# TLE9563 register map
Vendor: Infineon; File version: 0.2.0
Registers are 16-bit, read-write, reset 0x0 unless marked. A register's access mark holds for its fields unless they carry their own. Offsets are from the block's base; lines under a group give offsets from that group; [hi:lo] are bit positions; {n}, {i} and the like mark numbered series; 'fields as' and 'values as' point back to an identical list; <NAME> marks a mode.

## Memory map
0x00000000 TLE9563 size 0x4000 — TLE9563 Module

## TLE9563 — TLE9563 Module
Base 0x00000000
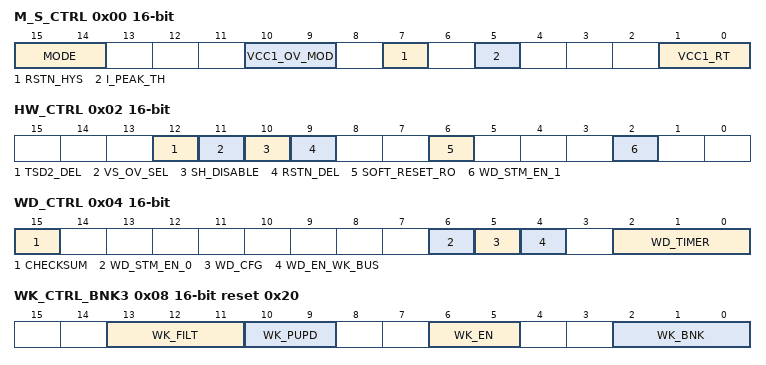
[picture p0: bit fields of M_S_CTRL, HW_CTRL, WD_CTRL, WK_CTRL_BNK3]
0x00 M_S_CTRL access per field (reset mask 0xE7) — Mode and Supply Control
  [15:14] MODE read-write-hardware — Device Mode Control
    0=NORMAL, Normal Mode; 1=SLEEP, Sleep Mode; 2=STOP, Stop Mode; 3=RESET, Device reset Soft reset is executed (configuration of RSTN triggering in bit SOFT_RESET_RO)
  [10:9] VCC1_OV_MOD read-write-hardware — Reaction in case of VCC1 Over Voltage
    0=NO, no reaction; 1=INTN, INTN event is generated; 2=RSTN, RSTN event is generated; 3=FAILSAFE, Fail-Safe Mode is entered
  [7] RSTN_HYS rw — VCC1 Undervoltage Reset Hysteresis Selection (see also Chapter 12.7.1 for more information)
    0=DEFAULT, default hysteresis applies as specified in the electrical characteristics table; 1=HIGHEST, the highest rising threshold (VRT1,R) is always used for the release of the undervoltage reset
  [5] I_PEAK_TH rw — VCC1 Active Peak Threshold Selection
    0=LOW, low VCC1 active peak threshold selected; 1=HIGH, high VCC1 active peak threshold selected
  [1:0] VCC1_RT rw — VCC1 Reset Threshold Control
    0=VRT1, Vrt1 selected (highest threshold); 1=VRT2, Vrt2 selected; 2=VRT3, Vrt3 selected; 3=VRT4, Vrt4 selected
0x02 HW_CTRL access per field (reset mask 0x5E) — Hardware Control
  [12] TSD2_DEL rw — TSD2 minimum Waiting Time Selection
    0=1s, Minimum waiting time until TSD2 is released again is always 1 s; 1=64s, Minimum waiting time until TSD2 is released again is 1 s, after >16 TSD2 consecutive events, it will extended x 64
  [11] VS_OV_SEL rw — VS OV comparator threshold change
    0=20V, Default threshold setting (VS,OVD1); 1=30V, increased threshold setting (VS,OVD2)
  [10] SH_DISABLE rw — Sample and hold circuitry disable
    0=ENABLED, Gate driver S&H circuitry enabled; 1=DISABLED, Gate driver S&H circuitry disabled
  [9] RSTN_DEL rw — Reset delay time
    0=10ms, Reset delay time 10 ms (tRD1); 1=2ms, Reset delay time to 2 ms (tRD2)
  [6] SOFT_RESET_RO rw — Soft Reset Configuration
    0=RSTN, RSTN will be triggered (pulled low) during a Soft Reset; 1=NO_RSTN, no RSTN trigger during a Soft Reset
  [2] WD_STM_EN_1 read-write-hardware — Watchdog Deactivation during Stop Mode, bit1
    0=ACTIVE, Watchdog is active in Stop Mode; 1=INACTIVE, Watchdog is deactivated in Stop Mode
0x04 WD_CTRL access per field (reset mask 0xF7) — Watchdog Control
  [15] CHECKSUM rw — Watchdog Setting Check Sum Bit
    0=0, Counts as 0 for checksum calculation; 1=1, Counts as 1 for checksum calculation
  [6] WD_STM_EN_0 read-write-hardware — Watchdog Deactivation during Stop Mode, bit0
    values as HW_CTRL.WD_STM_EN_1
  [5] WD_CFG rw — Watchdog Configuration
    0=TIMEOUT, Watchdog works as a Time-Out watchdog; 1=WINDOW, Watchdog works as a Window watchdog
  [4] WD_EN_WK_BUS read-write-hardware — Watchdog Enable after Bus Wake in Stop Mode
    0=DISABLED, Watchdog will not start after a CAN wake-up event; 1=ENABLED, Watchdog starts with a long open window after CAN Wake-up event
  [2:0] WD_TIMER read-write-hardware — Watchdog Timer Period
    0=10ms, 10ms; 1=20ms, 20ms; 2=50ms, 50ms; 3=100ms, 100ms; 4=200ms, 200ms; 5=500ms, 500ms; 6=1s, 1s; 7=10s, 10s
0x06 BUS_CTRL read-write-hardware reset 0x20 — CAN Control
  [2:0] CAN — HS-CAN Module Modes
    0=OFF, CAN OFF; 1=WAKE, CAN is wake capable (no SWK); 2=RECEIVE, CAN Receive Only Mode (no SWK); 3=NORMAL, CAN Normal Mode (no SWK); 4=OFF, CAN OFF; 5=WAKE_SWK, CAN is wake capable with SWK; 6=RECEIVE_SWK, CAN Receive Only Mode with SWK; 7=NORMAL_SWK, CAN Normal Mode with SWK
0x08 WK_CTRL_BNK3 reset 0x20 (reset mask 0x7F) — Wake-up Control
  [13:11] WK_FILT — Wake-up Filter Time Configuration
    0=16us, Filter with 16 i.ts filter time (static sensing); 1=64us, Filter with 64 i.ts filter time (static sensing); 2=TIMER1, Filtering at the end of the on-time; filter; 3=TIMER2, Filtering at the end of the on-time; filter; 4=SYNC, Filter at the end of settle time (80 i.ts), filter time of 16 i.ts (cyclic sensing) is selected, SYNC1)2); 5=, reserved; 6=, reserved; 7=, reserved
  [10:9] WK_PUPD — WKx Pull-Up/Pull-Down Configuration
    0=NO, No pull-up/pull-down selected; 1=PULL_DOWN, Pull-down resistor selected; 2=PULL_UP, Pull-up resistor selected3); 3=AUTO, Automatic switching to pull-up or pull-down
  [6:5] WK_EN — WKx Enable
    0=WK_OFF, WKx module OFF; 1=WK_ON, WKx module ON; 2=SYNC, OFF or (in case of WK4), it is configured as SYNC input; 3=OFF, OFF
  [2:0] WK_BNK — WKs input Banking
    3=WK4, WK4 Module (Bank 4); 4=WK5, WK5 Module (Bank 5)3); 5=, reserved; 6=, reserved; 7=, reserved
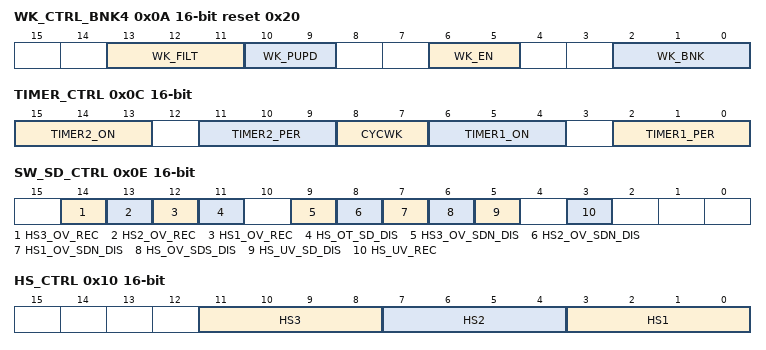
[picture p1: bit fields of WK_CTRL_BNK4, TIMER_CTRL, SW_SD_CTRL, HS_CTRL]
0x0A WK_CTRL_BNK4 reset 0x20 (reset mask 0x7F) — Wake-up Control
  fields as WK_CTRL_BNK3
0x0C TIMER_CTRL read-write-hardware (reset mask 0xFFEE) — Timer 1 and Timer2 Control and Selection
  [15:13] TIMER2_ON — Timer2 On-Time Configuration
    0=OFF_LOW, OFF / Low (timer not running, HSx output is low); 1=100us, 0.1ms on-time; 2=300us, 0.3ms on-time; 3=1ms, 1.0ms on-time; 4=10ms, 10ms on-time; 5=20ms, 20ms on-time; 6=OFF_HIGH, OFF / HIGH (timer not running, HSx; 7=, reserved, same behaviour as 110B
  [11:9] TIMER2_PER — Timer2 Period Configuration
    0=10ms, 10ms; 1=20ms, 20ms; 2=50ms, 50ms; 3=100ms, 100ms; 4=200ms, 200ms; 5=500ms, 500ms; 6=1s, 1s; 7=2s, 2s
  [8:7] CYCWK — Cyclic Wake Configuration
    0=DISABLED, Timer1 and Timer2 disabled as wake-up sources; 1=TIMER1, Timer1 is enabled as wake-up source (Cyclic Wake); 2=TIMER2, Timer2 is enabled as wake-up source (Cyclic Wake); 3=, reserved
  [6:4] TIMER1_ON — Timer1 On-Time Configuration
    0=OFF_LOW, OFF / Low (timer not running, HSx; 1=100us, 0.1ms on-time; 2=300us, 0.3ms on-time; 3=1ms, 1.0ms on-time; 4=10ms, 10ms on-time; 5=20ms, 20ms on-time; 6=OFF_HIGH, OFF / HIGH (timer not running, HSx output is high); 7=, reserved, same behaviour as 110B
  [2:0] TIMER1_PER — Timer1 Period Configuration
    values as TIMER2_PER
0x0E SW_SD_CTRL (reset mask 0xFB7A) — High-Side Switch Shutdown Control
  [14] HS3_OV_REC — Switch recovery after removal of VS Overvoltage for HS3
    0=DISABLED, Switch recovery is disabled; 1=PREVIOUS, Previous state before VS Overvoltage is enabled after Overvoltage considtion is removed
  [13] HS2_OV_REC — Switch recovery after removal of VS Overvoltage for HS2
    values as HS3_OV_REC
  [12] HS1_OV_REC — Switch recovery after removal of VS Overvoltage for HS1
    values as HS3_OV_REC
  [11] HS_OT_SD_DIS — Shutdown Disabling of all HS in case of Overtemperature event
    0=ALL, shudown for all HSx in case of Overtemperature; 1=INDIVIDUAL, individual shudown in case of Overtemperature
  [9] HS3_OV_SDN_DIS — Shutdown Disabling of HS3 in case of input supply overvoltage in Normal Mode
    0=ENABLED, shudown enabled in case of VS Overvoltage; 1=DISABLED, shudown disabled in case of VS Overvoltage
  [8] HS2_OV_SDN_DIS — Shutdown Disabling of HS2 in case of input supply overvoltage in Normal Mode
    0=ENABLED, shudown enabled in case of VS Overvoltage; 1=DIASBLED, shudown disabled in case of VS Overvoltage
  [7] HS1_OV_SDN_DIS — Shutdown Disabling of HS1 in case of input supply overvoltage in Normal Mode
    values as HS3_OV_SDN_DIS
  [6] HS_OV_SDS_DIS — Shutdown Disabling of HSx in case of input supply overvoltage in Stop Mode or Sleep Mode
    values as HS3_OV_SDN_DIS
  [5] HS_UV_SD_DIS — Shutdown Disabling of HSx in case of input supply undervoltage
    0=ENABLED, shudown enabled in case of VS Undervoltage; 1=DISABLED, shudown disabled in case of VS Undervoltage
  [3] HS_UV_REC — Switch recovery after removal of Undervoltage for HSx
    0=DISABLED, Switch recovery is disabled; 1=PREVIOUS, Previous state before VS
0x10 HS_CTRL read-write-hardware (reset mask 0xFF0E) — High-Side Switch Control
  [all] fields
    0=OFF, OFF; 1=ON, ON; 2=TIMER1, Controlled by Timer1; 3=TIMER2, Controlled by Timer2; {v}=PWM{v-3}, Controlled by PWM{v-3} (v=4..7); 8=WK4_SYNC, Synchronized with WK4/SYNC
  [11:8] HS3 — HS3 Configuration
  [7:4] HS2 — HS2 Configuration
  [3:0] HS1 — HS1 Configuration
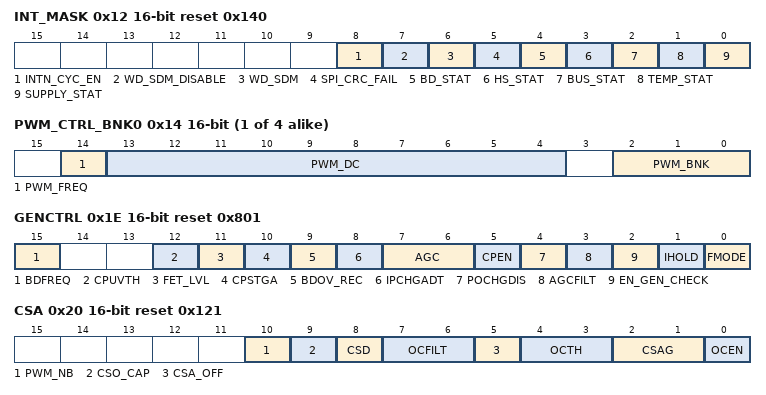
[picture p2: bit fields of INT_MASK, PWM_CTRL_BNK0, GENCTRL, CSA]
0x12 INT_MASK reset 0x140 (reset mask 0xFF00) — Interrupt Mask Control
  [8] INTN_CYC_EN — Periodical INTN generation
    0=DISABLED, no periodical INTN event generated in case of pending interrupts; 1=ENABLED, periodical INTN event generated in case of pending interrupts
  [7] WD_SDM_DISABLE — Disable Watchdog in Software Development Mode
    0=ENABLED, WD is enabled in Software Development Mode; 1=DISABLED, WD is disabled in Software Development Mode
  [6] WD_SDM — Watchdog failure in Software Development Mode
    0=DISABLED, no INTN event generated in case of WD trigger failure in Software Development Mode; 1=ENABLED, one INTN event is generated in case of WD trigger failure in Software Development Mode
  [5] SPI_CRC_FAIL — SPI and CRC interrupt generation
    0=DISABLED, no INTN event generated in case of SPI_FAIL or CRC_FAIL; 1=ENABLED, one INTN event is generated n case of SPI_FAIL or CRC_FAIL
  [4] BD_STAT — Bridge Driver Interrupt generation
    0=DISABLED, no INTN event generated in case BD_STAT (on Status Information Field) is set; 1=ENABLED, one INTN event generated in case BD_STAT (on Status Information Field) is set
  [3] HS_STAT — High Side Interrupt generation
    0=DISABLED, no INTN event generated in case HS_STAT (on Status Information Field) is set; 1=ENABLED, one INTN event generated in case HS_STAT (on Status Information Field) is set
  [2] BUS_STAT — BUS Interrupt generation
    0=DISABLED, no INTN event generated in case BUS_STAT (on Status Information Field) is set; 1=ENABLED, one INTN event generated in case BUS_STAT (on Status Information Field) is set
  [1] TEMP_STAT — Temperature Interrupt generation
    0=DISABLED, no INTN event generated in case TEMP_STAT (on Status Information Field) is set; 1=ENABLED, one INTN event generated in case TEMP_STAT (on Status Information Field) is set
  [0] SUPPLY_STAT — SUPPLY Status Interrupt generation
    0=DISABLED, no INTN event generated in case SUPPLY_STAT (on Status Information Field) is set; 1=ENABLED, one INTN event generated in case SUPPLY_STAT (on Status Information Field) is set
{0x14+2i} PWM_CTRL_BNK{i} (reset mask 0xFF7E) (i=0..3) — PWM Configuration Control
  [14] PWM_FREQ — PWM generator Frequency Setting
    0=100Hz, 100Hz is selected; 1=200Hz, 200Hz is selected
  [13:4] PWM_DC — PWM Duty Cycle Setting (bit4 = LSB; bit13 = MSB)
  [2:0] PWM_BNK — Internal PWM generator selection
    {v}=PWM{v+1}, PWM{v+1} Module (v=0..3)
0x1C SYS_STAT_CTRL (reset mask 0xFFFE) — System Status Control
  [15:0] SYS_STAT — System Status Control (bit0=LSB; bit15=MSB) Dedicated bytes for system configuration, access only by microcontroller. Cleared after power up and soft reset.
0x1E GENCTRL reset 0x801 (reset mask 0xFF9E) — General Bridge Control
  [15] BDFREQ — Bridge driver synchronization frequency
    0=18MHz, typ. 18.75 MHz (default); 1=37MHz, typ. 37.5 MHz
  [12] CPUVTH — Charge pump under voltage (referred to VS)
    0=TH1, (default) CPUV threshold 1 for FET_LVL = 0, CPUV threshold 1 for FET_LVL = 1; 1=TH2, CPUV threshold 2 for FET_LVL = 0, CPUV threshold 2 for FET_LVL = 1
  [11] FET_LVL — External MOSFET normal / logic level selection
    0=LOGIC, Logic level MOSFET selected; 1=NORMAL, Normal level MOSFET selected(default)
  [10] CPSTGA — Automatic switchover between dual and single charge pump stage
    0=INACTIVE, Automatic switch over deactivated (default); 1=ACTIVE, Automatic switch over activated
  [9] BDOV_REC — Bridge driver recover from VS and VSINT Overvoltage
    0=INACTIVE, Recover deactivated (default); 1=ACTIVE, Recover activated
  [8] IPCHGADT — Adaptation of the pre-charge and pre-discharge current
    0=1STEP, 1 current step (default); 1=2STEPS, 2 current steps
  [7:6] AGC — Adaptive gate control
    0=INACTIVE1, (default) Adaptive gate control disabled, pre-charge and pre-discharge disabled; 1=INACTIVE2, Adaptive gate control disabled, precharge is enabled with IPRECHG = IPCHGINIT, predischarge is enabled with IPREDCHG = IPDCHGINIT; 2=ACTIVE, Adaptive gate control enabled, IPRECHG and IPREDCHG are self adapted; 3=reserved, Adaptive gate control enabled, IPRECHG and IPREDCHG are self adapted
  [5] CPEN
    0=DISABLED, Charge pump disabled (default); 1=ENABLED, Charge pump enabled
  [4] POCHGDIS — Postcharge disable bit
    0=ENABLED, The postcharge phase is enabled during PWM (default); 1=DISABLED, The postcharge phase is disabled during PWM
  [3] AGCFILT — Filter for adaptive gate control
    0=NO_FILT, No filter applied (default); 1=FILT_APPL, Filter applied
  [2] EN_GEN_CHECK — Detection of active / FW MOSFET
    0=DISABLED, Detection disabled (default); 1=ENABLED, Detection enabled
  [1] IHOLD — Gate driver hold current IHOLD
    0=TH1, (default) Charge 'CHG15, discharge 'DCHG15; 1=TH2, Charge 'CHG20, discharge 'DCHG20
  [0] FMODE — Frequency modulation of the charge pump
    0=NO, No modulation; 1=15KHz, Modulation frequency 15.6 kHz (default)
0x20 CSA reset 0x121 (reset mask 0xFF06) — Current sense amplifier
  [10] PWM_NB — Selection of 3 or 6 PWM inputs
    0=3PWM, 3 PWM inputs (default); 1=6PWM, 6 PWM inputs
  [9] CSO_CAP — Capacitance connected to the current sense amplifier output (CCSO), see also Chapter 12.12.4
    0=400pF, CCSO < 400 pF (default); 1=2nF, 400 pF < CCSO < 2.2 nF
  [8] CSD — Direction of the current sense amplifier
    0=UNI, Unidirectional; 1=BI, Bidirectional (default)
  [7:6] OCFILT — Overcurrent filter time of CSO
    0=6us, 6 us (default); 1=10us, 10 us; 2=50us, 50 us; 3=100us, 100 us
  [5] CSA_OFF
    0=CSA_ON, CSA enabled; 1=CSA_OFF, CSA disabled (default)
  [4:3] OCTH — Overcurrent detection threshold of CSO
    0=TH1, VCSO > VCC1/2+2 x VCC1/20 or VCSOx< VCC1/2- 2x VCC1/20 (default); 1=TH2, VCSO > VCC1/2+ 4x VCC1/20 or VCSOx< VCC1/2- 4x VCC1/20; 2=TH3, VCSO > VCC1/2+ 5 x VCC1/20 or VCSOx< VCC1/2- 5 xVCC1/20; 3=TH4, VCSO > VCC1/2+ 6x VCC1/20 or VCSOx< VCC1/2- 6x VCC1/20
  [2:1] CSAG — Gain of the current sense amplifier
    0=10VV, GDIFF10 (default); 1=20VV, GDIFF20; 2=40VV, GDIFF40; 3=60VV, GDIFF60
  [0] OCEN — Overcurrent shutdown Enable
    0=DISABLED, Disabled; 1=ENABLED, Enabled (default)
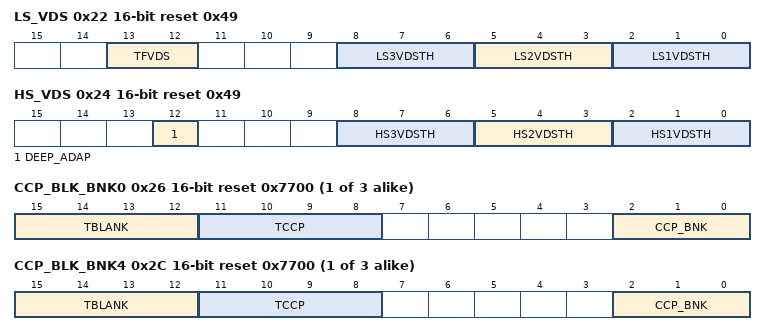
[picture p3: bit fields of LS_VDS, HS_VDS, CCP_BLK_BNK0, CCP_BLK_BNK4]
0x22 LS_VDS reset 0x49 (reset mask 0xFF30) — VDS monitoring threshold LS1-3
  [13:12] TFVDS — Filter time of drain-source voltage monitoring
    0=500ns, 0.5 us (default); 1=1us, 1 us; 2=2us, 2 us; 3=6us, 6 us
  [8:6] LS3VDSTH — LS3 drain-source overvoltage threshold
    0=160mV, 0.16 V; 1=200mV, 0.20 V (default); 2=300mV, 0.30 V; 3=400mV, 0.40 V; 4=500mV, 0.50 V; 5=600mV, 0.60 V; 6=800mV, 0.80 V; 7=2V, 2.0 V
  [5:3] LS2VDSTH — LS2 drain-source overvoltage threshold
    0=160mV, 0.16V; 1=200mV, 0.20 V (default); 2=300mV, 0.30 V; 3=400mV, 0.40 V; 4=500mV, 0.50 V; 5=600mV, 0.60 V; 6=800mV, 0.80 V; 7=2V, 2.0 V
  [2:0] LS1VDSTH — LS1 drain-source overvoltage threshold
    values as LS3VDSTH
0x24 HS_VDS reset 0x49 (reset mask 0xFF10) — VDS monitoring threshold HS1-3
  [12] DEEP_ADAP — Deep adaptation enable
    0=NO_DEEP_ADAP, Deep adaptation disabled (default); 1=DEEP_ADAP, Deep adaptation enabled
  [8:6] HS3VDSTH — HS3 drain-source overvoltage threshold
    values as LS_VDS.LS3VDSTH
  [5:3] HS2VDSTH — HS2 drain-source overvoltage threshold
    values as LS_VDS.LS3VDSTH
  [2:0] HS1VDSTH — HS1 drain-source overvoltage threshold
    values as LS_VDS.LS3VDSTH
{0x26+2i} CCP_BLK_BNK{i} reset 0x7700 (reset mask 0xFFFE) (i=0..2) — CCP and times selection
  [15:12] TBLANK — Blank time
  [11:8] TCCP — Cross-current protection time
  [2:0] CCP_BNK — Cross-current and time banking
    0=ACT_HB1, Active blank and cross-current prot. times for HB1 (default); 1=ACT_HB2, Active blank and cross-current prot. times for HB2; 2=ACT_HB3, Active blank and cross-current prot. times for HB3; 3=RES, reserved; 4=FW_HB1, FW blank and cross-current prot. times for HB1; 5=FW_HB2, FW blank and cross-current prot. times for HB2; 6=FW_HB3, FW blank and cross-current prot. for times for HB3; 7=RES, reserved
{0x24+2i} CCP_BLK_BNK{i} reset 0x7700 (reset mask 0xFFFE) (i=4..6) — CCP and times selection
  fields as CCP_BLK_BNK0
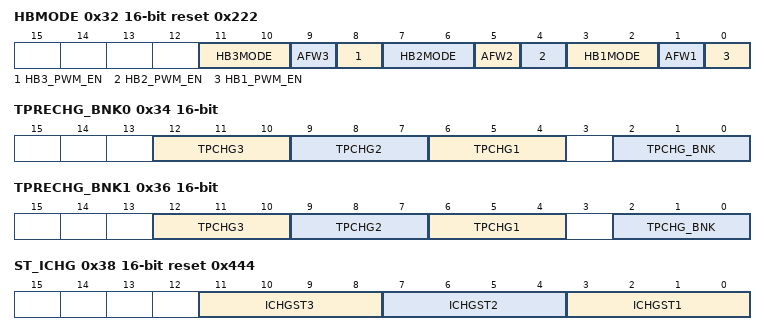
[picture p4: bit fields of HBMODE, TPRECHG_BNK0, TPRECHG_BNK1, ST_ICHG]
0x32 HBMODE reset 0x222 (reset mask 0xFF0E) — Half-Bridge MODE
  [11:10] HB3MODE — Half-bridge 3 MODE selection
    0=PASSIVE_OFF, LS3 and HS3 are off by passive discharge (default); 1=LS3_ON, LS3 is ON; 2=HS3_ON, HS3 is ON; 3=ACTIVE_OFF, LS3 and HS3 kept off by the active discharge
  [9] AFW3 — Active freewheeling for half-bridge 3 during PWM
    0=DISABLED, active freewheeling disabled; 1=ENABLED, active freewheeling enabled (default)
  [8] HB3_PWM_EN — PWM mode for half-bridge 3
    0=INACTIVE, PWM deactivated for HB2(default); 1=ACTIVE, PWM activated for HB2
  [7:6] HB2MODE — Half-bridge 2 MODE selection
    0=PASSIVE_OFF, LS2 and HS2 are off by passive discharge (default); 1=LS2_ON, LS2 is ON; 2=HS2_ON, HS2 is ON; 3=ACTIVE_OFF, LS2 and HS2 kept off by the active discharge
  [5] AFW2 — Active freewheeling for half-bridge 2 during PWM
    values as AFW3
  [4] HB2_PWM_EN — PWM mode for half-bridge 2
    values as HB3_PWM_EN
  [3:2] HB1MODE — Half-bridge 1 MODE selection
    0=PASSIVE_OFF, LS1 and HS1 are off by passive discharge (default); 1=LS1_ON, LS1 is ON; 2=HS1_ON, HS1 is ON; 3=ACTIVE_OFF, LS1 and HS1 kept off by the active discharge
  [1] AFW1 — Active freewheeling for half-bridge 1 during PWM
    values as AFW3
  [0] HB1_PWM_EN — PWM mode for half-bridge 1
    0=INACTIVE, PWM deactivated for HB1 (default); 1=ACTIVE, PWM activated for HB1
0x34 TPRECHG_BNK0 (reset mask 0xFF1E) — HB pre-charge and pre-discharge time
  [12:10] TPCHG3 — If TPCHG_BNK=0 precharge time of HB 3, If TPCHG_BNK=1 predischarge time of HB 3
  [9:7] TPCHG2 — If TPCHG_BNK=0 precharge time of HB 2, If TPCHG_BNK=1 predischarge time of HB 2
  [6:4] TPCHG1 — If TPCHG_BNK=0 precharge time of HB 1, If TPCHG_BNK=1 predischarge time of HB 1
  [2:0] TPCHG_BNK — Precharge/predischarge time selection
    0=PRECHARGE, Precharge time selected (default); 1=PREDISCHARGE, Predischarge time selected
0x36 TPRECHG_BNK1 (reset mask 0xFF1E) — HB pre-charge and pre-discharge time
  fields as TPRECHG_BNK0
0x38 ST_ICHG reset 0x444 (reset mask 0xFF0E) — Static charge/discharge current
  [all] fields
    4=Default - charge 'CHG16,15.3 mA typ., discharge
  [11:8] ICHGST3 — Static charge and discharge currents of HB3
  [7:4] ICHGST2 — Static charge and discharge currents of HB2
  [3:0] ICHGST1 — Static charge and discharge currents of HB1
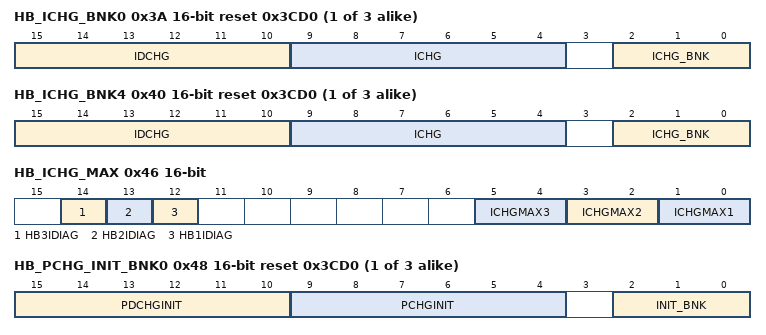
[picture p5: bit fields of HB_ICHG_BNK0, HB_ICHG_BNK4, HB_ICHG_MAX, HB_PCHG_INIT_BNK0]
{0x3A+2i} HB_ICHG_BNK{i} reset 0x3CD0 (reset mask 0xFFFE) (i=0..2) — HB charge/discharge currents for PWM operation
  [15:10] IDCHG — If ICHG_BNK =0xxB Discharge current of HBx active MOSFET
  [9:4] ICHG — If ICHG_BNK=0xxB Charge current of HBx active MOSFET
  [2:0] ICHG_BNK — Banking bits for charge and discharge currents of active MOSFETs
    0=ACT_HB1, Active MOSFET of HB1 is selected (default); 1=ACT_HB2, Active MOSFET of HB2 is selected; 2=ACT_HB3, Active MOSFET of HB3 is selected; 3=RES, reserved; 4=FW_HB1, FW MOSFET of HB1 is selected; 5=FW_HB2, FW MOSFET of HB2 is selected; 6=FW_HB3, FW MOSFET of HB3 is selected; 7=RES, reserved
{0x38+2i} HB_ICHG_BNK{i} reset 0x3CD0 (reset mask 0xFFFE) (i=4..6) — HB charge/discharge currents for PWM operation
  fields as HB_ICHG_BNK0
0x46 HB_ICHG_MAX (reset mask 0x7F) — HB max. pre-charge/pre-discharge in PWM operation current and diagnostic pull-down
  [14] HB3IDIAG — Control of HB3 off-state current source and current sink
    0=INACTIVE, Pull-down deactivated (default); 1=ACTIVE, Pull-down activated
  [13] HB2IDIAG — Control of HB2 pull-down for off-state diagnostic
    values as HB3IDIAG
  [12] HB1IDIAG — Control of HB1 pull-down for off-state diagnostic
    values as HB3IDIAG
  [5:4] ICHGMAX3 — Maximum drive current of HB3 during the pre-charge and pre-discharge phases1)
    0=31mA, charge ICHG24 typ. 31.6 mA, discharge IDCHG24 typ. 30.9 mA (default); 1=52mA, charge ICHG32 typ. 52.5 mA, discharge IDCHG32 typ. 51.5 mA; 2=112mA, charge ICHG52 typ. 112.2mA, discharge IDCHG52 typ. 110.8 mA; 3=150mA, charge ICHG63 typ. 150 mA, discharge IDCHG63 typ. 150 mA
  [3:2] ICHGMAX2 — Maximum drive current of HB2 during the pre-charge phase and pre-discharge phases1)
    values as ICHGMAX3
  [1:0] ICHGMAX1 — Maximum drive current of HB1 during the pre-charge and pre-discharge phases1)
    values as ICHGMAX3
{0x48+2i} HB_PCHG_INIT_BNK{i} reset 0x3CD0 (reset mask 0xFFFE) (i=0..2) — HBx pre-charge/pre-discharge initialization configuration in PWM operation
  [15:10] PDCHGINIT — Initial predischarge current of HBx, IPDCHGINITx The INIT_BNK bits select the addressed half-bridge Default 001111B
  [9:4] PCHGINIT — Initial precharge current of HBx, IPCHGINITx The INIT_BNK bits select the addressed half-bridge Default 001101B Refer to Table 34
  [2:0] INIT_BNK — Banking bits for Precharge an Predischarge Initial
    0=HB1, precharge/discharge init. for HB1 selected (default); 1=HB2, precharge/discharge init. for HB2 selected; 2=HB3, precharge/discharge init. for HB3 selected; 2=RES, reserved; 3=RES, reserved
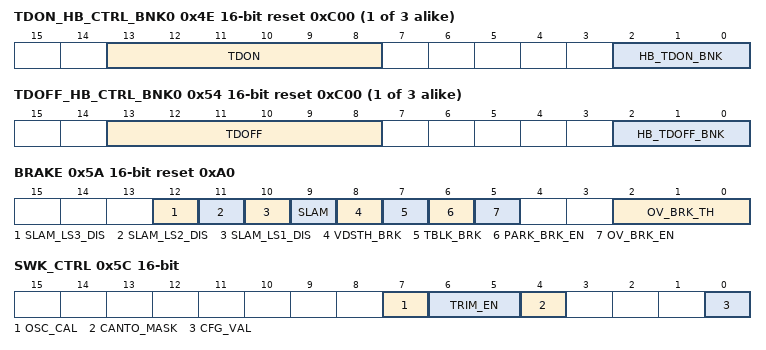
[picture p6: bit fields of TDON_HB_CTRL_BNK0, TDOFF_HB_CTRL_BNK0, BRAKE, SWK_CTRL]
{0x4E+2i} TDON_HB_CTRL_BNK{i} reset 0xC00 (reset mask 0x3F3E) (i=0..2) — HBx inputs TDON configuration
  [13:8] TDON — Turn-on delay time of active MOSFET of HBx
    12=Default 00 640 ns typ
  [2:0] HB_TDON_BNK — Banking bits for turn-on delay time
    0=HB1, tDON of HB1 selected (default); 1=HB2, tDON of HB2 selected; 2=HB3, tDON of HB3 selected; 3=RES, reserved
{0x54+2i} TDOFF_HB_CTRL_BNK{i} reset 0xC00 (reset mask 0x3F3E) (i=0..2) — HBx TDOFF configuration
  [13:8] TDOFF — Turn-off delay time of active MOSFET of HBx The HB_TDOFF_BNK bits selects the turn-off delay time of the active MOSFET of the half-bridge HBx Nominal tDOFF = 53.3 ns x TDOFF[50]D
    12=Default 0000 640 ns
  [2:0] HB_TDOFF_BNK — Banking bits for turn-off delay time
    0=HB1, tDOFF of HB1 selected (default); 1=HB2, tDOFF of HB2 selected; 2=HB3, tDOFF of HB3 selected
0x5A BRAKE reset 0xA0 (reset mask 0xFF1E) — Brake control
  [12] SLAM_LS3_DIS — LS3 output disable during SLAM mode
    0=ACTIVE, LS3 control active in Slam mode (default); 1=DISABLED, LS3 control disabled in Slam mode
  [11] SLAM_LS2_DIS — LS2 output disable during SLAM mode
    0=ACTIVE, LS2 control active in Slam mode (default); 1=DISABLED, LS2 control disabled in Slam mode
  [10] SLAM_LS1_DIS — LS1 output disable during SLAM mode
    0=ACTIVE, LS1 control active in Slam mode (default); 1=DISABLED, LS1 control disabled in Slam mode
  [9] SLAM — Slam mode
    0=INACTIVE, Slam mode deactivated (default); 1=AVTIVE, Slam mode activated
  [8] VDSTH_BRK — VDS Overvoltage for LS1-3 during braking
    0=800mV, VVDSMONTH0_BRAKE, 0.8 V, typ. (default); 1=220mV, VVDSMONTH1_BRAKE, 0.22 V typ
  [7] TBLK_BRK — Blank time of VDS overvoltage during braking
    0=7uS, tBLK_BRAKE1,7 us typ; 1=11uS, tBLK_BRAKE2, 11 us typ. (default)
  [6] PARK_BRK_EN — Parking brake enable
    0=DISABLED, Parking brake disabled (default); 1=ENABLED, Parking brake enabled
  [5] OV_BRK_EN — Overvoltage brake enable
    0=DISABLED, Overvoltage brake disabled; 1=ENABLED, Overvoltage brake enabled (default)
  [2:0] OV_BRK_TH — Overvoltage brake threshold
    0=27V, typ. 27V (default); {v}={v+27}V, typ. {v+27}V (v=1..7)
0x5C SWK_CTRL access per field — CAN Selective Wake Control
  [7] OSC_CAL rw — Oscillator Calibration Mode
    0=DISABLED, Oscillator Calibration is disabled; 1=ENABLED, Oscillator Calibration is enabled
  [6:5] TRIM_EN rw — (Un)locking mechanism of oscillator recalibration
    0=LOCKED, locked; 1=LOCKED, locked; 2=LOCKED, locked; 3=UNLOCKED, unlocked
  [4] CANTO_MASK rw — CAN Time Out Masking
    0=MASKED, CAN time-out is masked - no interrupt (on pin INTN) is triggered; 1=UNMASKED, CAN time-out is signaled on INTN
  [0] CFG_VAL read-write-hardware — SWK Configuration valid
    0=NOT_VALID, Configuration is not valid (SWK not possible); 1=VALID, SWK configuration valid, needs to be set to enable SWK
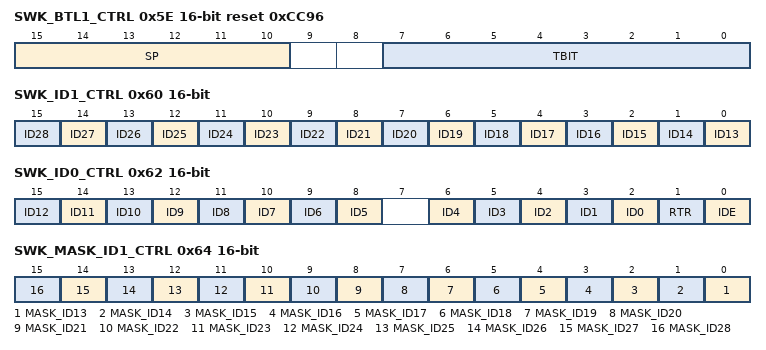
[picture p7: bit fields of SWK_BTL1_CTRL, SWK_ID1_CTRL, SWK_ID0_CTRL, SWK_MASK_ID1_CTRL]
0x5E SWK_BTL1_CTRL reset 0xCC96 (reset mask 0xFF) — SWK Bit Timing Control
  [15:10] SP — Sampling Point Position
  [7:0] TBIT — Number of Time Quanta in a Bit Time
0x60 SWK_ID1_CTRL (reset mask 0xFFFE) — SWK WUF Identifier bits 28...13
  [n-13] ID{n} (n=13..28) — WUF Identifier Bit {n}
0x62 SWK_ID0_CTRL (reset mask 0xFFFE) — SWK WUF Identifier bits 12...0
  [n+3] ID{n} (n=5..12) — WUF Identifier Bit {n}
  [n+2] ID{n} (n=0..4) — WUF Identifier Bit {n}
  [1] RTR — Remote Transmission Request Field (acc. ISO11898-22016)
    0=NORMAL, Normal Data Frame; 1=REMOTE, Remote Transmission Request
  [0] IDE — Identifier Extension Bit
    0=STD, Standard Identifier Length (11 bit); 1=EXT, Extended Identifier Length (29 bit)
0x64 SWK_MASK_ID1_CTRL (reset mask 0xFFFE) — SWK WUF Identifier Mask bits 28...13
  [all] fields
    0=UNMASKED, Unmasked - bit is ignored; 1=MASKED, Masked - bit is compared in CAN frame
  [n-13] MASK_ID{n} (n=13..28) — WUF Identifier Mask Bit {n}
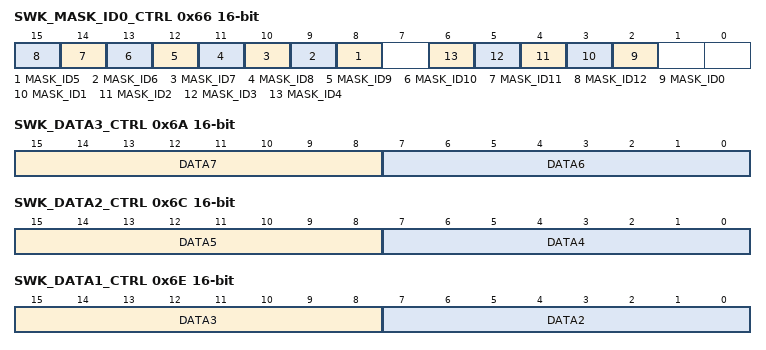
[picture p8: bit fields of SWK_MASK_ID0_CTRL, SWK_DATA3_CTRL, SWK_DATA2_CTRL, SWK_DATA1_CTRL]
0x66 SWK_MASK_ID0_CTRL — SWK WUF Identifier Mask bits 12...0
  [all] fields
    values as the fields of SWK_MASK_ID1_CTRL
  [n+3] MASK_ID{n} (n=5..12) — WUF Identifier Mask Bit {n}
  [n+2] MASK_ID{n} (n=0..4) — WUF Identifier Mask Bit {n}
0x68 SWK_DLC_CTRL — SWK Frame Data Length Code Control
  [3:0] DLC — Payload length in number of bytes
    0=0, Frame Data Length = 0 or cleared; {v}={v}, Frame Data Length = {v} (v=1..7); 8=8, to 1111B Frame Data Length = 8
0x6A SWK_DATA3_CTRL (reset mask 0xFFFE) — SWK Data7-Data6 Register
  [15:8] DATA7 — Data7 byte content(bit0=LSB; bit7=MSB)
  [7:0] DATA6 — Data6 byte content(bit0=LSB; bit7=MSB)
0x6C SWK_DATA2_CTRL (reset mask 0xFFFE) — SWK Data5-Data4 Register
  [15:8] DATA5 — Data5 byte content(bit0=LSB; bit7=MSB)
  [7:0] DATA4 — Data4 byte content(bit0=LSB; bit7=MSB)
0x6E SWK_DATA1_CTRL (reset mask 0xFFFE) — SWK Data3-Data2 Register
  [15:8] DATA3 — Data3 byte content(bit0=LSB; bit7=MSB)
  [7:0] DATA2 — Data2 byte content(bit0=LSB; bit7=MSB)
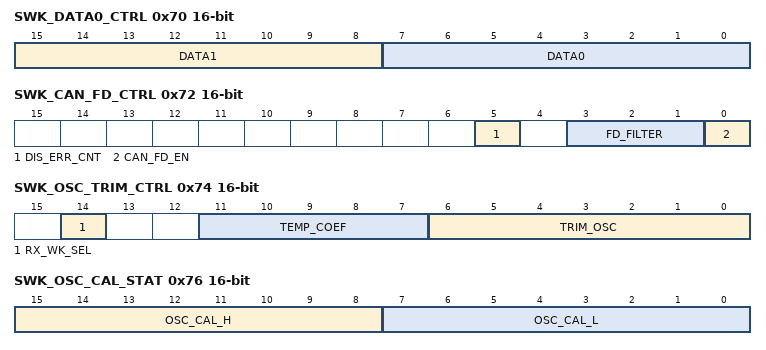
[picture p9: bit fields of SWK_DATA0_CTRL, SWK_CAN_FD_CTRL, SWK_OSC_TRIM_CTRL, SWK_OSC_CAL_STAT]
0x70 SWK_DATA0_CTRL (reset mask 0xFFFE) — SWK Data1-Data0 Register
  [15:8] DATA1 — Data1 byte content(bit0=LSB; bit7=MSB)
  [7:0] DATA0 — Data0 byte content(bit0=LSB; bit7=MSB)
0x72 SWK_CAN_FD_CTRL access per field — CAN FD Configuration Control Register
  [5] DIS_ERR_CNT read-write-hardware — Error Counter Disable Function
    0=ENABLED, Error Counter is enabled during SWK; 1=DISABLED, Error counter is disabled during SWK only if CAN_FD_EN = '1'
  [3:1] FD_FILTER rw — CAN FD Dominant Filter Time
    0=50ns, 50 ns; 1=100ns, 100 ns; 2=150ns, 150 ns; 3=200ns, 200 ns; 4=250ns, 250 ns; 5=300ns, 300 ns; 6=350ns, 350 ns; 7=775ns, 775 ns
  [0] CAN_FD_EN rw — Enable CAN FD Tolerant Mode
    0=DISABLED, CAN FD Tolerant Mode disabled; 1=ENABLED, CAN FD Tolerant Mode enabled
0x74 SWK_OSC_TRIM_CTRL (reset mask 0xFF4E) — SWK Oscillator Trimming and option Register
  [14] RX_WK_SEL — SWK Receiver selection (only accessible if TRIM_EN = '11')
    0=LOW_POWER, Low-Power Receiver selected during SWK; 1=STD, Standard Receiver selected during SWK
  [11:7] TEMP_COEF — Trimming of temp_coef (only writable if TRIM_EN = '11')
  [6:0] TRIM_OSC — Trimming of oscillator (only writable if
0x76 SWK_OSC_CAL_STAT ro (reset mask 0xFFFE) — SWK Oscillator Calibration Register
  [15:8] OSC_CAL_H — Oscillator Calibration High Register
  [7:0] OSC_CAL_L — Oscillator Calibration Low Register
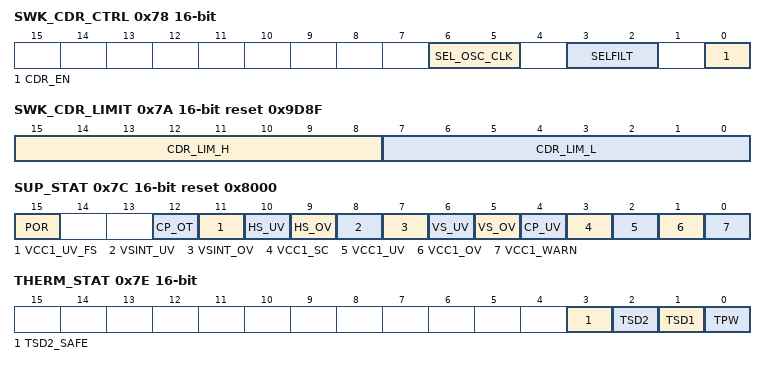
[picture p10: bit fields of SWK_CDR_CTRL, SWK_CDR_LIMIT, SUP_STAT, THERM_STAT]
0x78 SWK_CDR_CTRL — Clock Data Recovery Control Register
  [6:5] SEL_OSC_CLK — Input Frequency for CDR module
  [3:2] SELFILT — Select Time Constant of Filter
    0=8, Time constant 8; 1=16, Time constant 16 (default); 2=32, Time constant 32; 3=ADAPTIVE, adapt distance between falling edges 2, 3 bit Time constant 32; distance between falling edges 4, 5, 6, 7, 8 bit Time constant 16; distance between falling edges 9, 10 bit Time constant 8
  [0] CDR_EN — Enable CDR
    0=DISABLED, CDR disabled; 1=ENABLED, CDR enabled
0x7A SWK_CDR_LIMIT reset 0x9D8F (reset mask 0xFFFE) — SWK Clock Data Recovery Limit Control
  [15:8] CDR_LIM_H — Upper Bit Time Detection Range of Clock and Data
  [7:0] CDR_LIM_L — Lower Bit Time Detection Range of Clock and Data
0x7C SUP_STAT read-clear reset 0x8000 (reset mask 0xFF9E) — Supply Voltage Fail Status
  [15] POR — Power-On reset detection
    0=NO_POR, No POR; 1=POR, POR occurred
  [12] CP_OT — Charge pump overtemperature
    0=NO_CP_OT, No charge pump OT detected; 1=CP_OT, Charge pump OT detected
  [11] VCC1_UV_FS — 4th consecutive VCC1 UV-Detection
    0=NO_FAILSAFE, No Fail-Safe Mode entry due to 4th consecutive VCC1_UV; 1=FAILSAFE, Fail-Safe Mode entry due to 4th consecutive VCC1_UV
  [10] HS_UV — HS Supply UV-Detection
    0=NO_UV, No Undervoltage; 1=UV_EVENT, HS Supply Undervoltage detected
  [9] HS_OV — HS Supply OV-Detection
    0=NO_OV, No Overvoltage; 1=OV_EVENT, HS Supply Overvoltage detected
  [8] VSINT_UV — VSINT UV-Detection
    0=NO_UV, No Undervoltage; 1=UV_EVENT, VSINT Undervoltage detected
  [7] VSINT_OV — VSINT OV-Detection
    0=NO_OV, No Overvoltage; 1=OV_EVENT, VSINT Overvoltage detected
  [6] VS_UV — VS Undervoltage Detection (VS,UV)
    0=NO_VS, No VS undervoltage detected; 1=VS_EVENT, VS undervoltage detected (detection is only active when VCC1 is enabled)
  [5] VS_OV — VS Overvoltage Detection (VS,OV)
    0=NO_OV, No VS overvoltage detected; 1=OV_EVENT, VS overvoltage detected (detection is only active when VCC1 is enabled)
  [4] CP_UV
    0=NO_UV, No CP undervoltage detected; 1=UV_EVENT, CP undervoltage detected
  [3] VCC1_SC
    0=NO_SC, No VCC1 short to GND detected; 1=SC_EVENT, VCC1 short to GND
  [2] VCC1_UV — VCC1 UV-Detection (due to Vrtx reset)
    0=NO_UV, No VCC1_UV detection; 1=UV_EVENT, VCC1 undervoltage detected
  [1] VCC1_OV — VCC1 Overvoltage Detection
    0=NO_OV, No VCC1 overvoltage warning; 1=OV_EVENT, VCC1 overvoltage detected
  [0] VCC1_WARN — VCC1 Undervoltage Prewarning
    0=NO_UV, No VCC1 undervoltage prewarning; 1=UV_PREWARN, VCC1 undervoltage prewarning detected
0x7E THERM_STAT read-clear — Thermal Protection Status
  [3] TSD2_SAFE — TSD2 Thermal Shut-Down Safe State Detection
    0=NO_TSD2_SF, No TSD2 safe state detected; 1=TSD2_SF, TSD2 safe state detected >16 consecutive TSD2 events occurred, next TSD2 waiting time will be 64s
  [2] TSD2 — TSD2 Thermal Shut-Down Detection
    0=NO_TSD2, No TSD2 event; 1=TSD2_EVENT, TSD2 OT detected - leading to Fail-Safe Mode
  [1] TSD1 — TSD1 Thermal Shut-Down Detection
    0=NO_TSD1, No TSD1 fail; 1=TSD1_EVENT, TSD1 OT detected (affected module is disabled)
  [0] TPW — Thermal Pre Warning
    0=NO_TPW, No Thermal Pre warning; 1=TPW, Thermal Pre warning detected
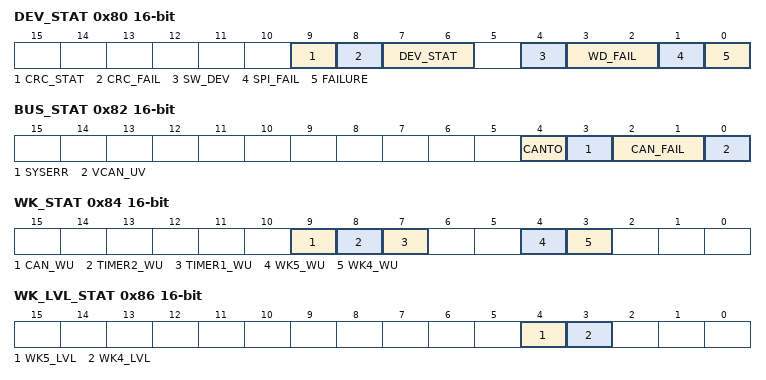
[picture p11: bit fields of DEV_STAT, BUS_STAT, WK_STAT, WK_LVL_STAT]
0x80 DEV_STAT access per field (reset mask 0xDF02) — Device Information Status
  [9] CRC_STAT ro — CRC STAT Information
    0=DISABLED, CRC disabled; 1=ENABLED, CRC enabled
  [8] CRC_FAIL read-clear — CRC Fail Information1)
    0=NO_FAIL, No CRC Failure; 1=FAIL, CRC Failure detected
  [7:6] DEV_STAT read-clear — Device Status before Restart Mode
    0=CLEARED, Cleared (Register must be actively cleared); 1=RESTART, Restart due to failure (WD fail, TSD2, VCC1_UV, trial to access Sleep Mode without any wake source activated); also after a wake from Fail-Safe Mode; 2=SLEEP, Sleep Mode; 3=, reserved
  [4] SW_DEV rh — Status of Operating Mode
    0=NORMAL, Normal operation; 1=SW_DEV, Software Development Mode is enabled
  [3:2] WD_FAIL rh — Number of WD-Failure Events
    0=NO_FAIL, No WD Fail; 1=1x, 1x WD Fail,; 2=2x, 2x WD Fail; 3=3x, more than 3xWD Fail
  [1] SPI_FAIL read-clear — SPI Fail Information
    0=NO_FAIL, No SPI fail; 1=INVALID, Invalid SPI command detected
  [0] FAILURE read-clear — Failure detection
    0=NO_FAIL, No Failure; 1=FAIL, Failure occured
0x82 BUS_STAT read-clear — Bus Communication Status
  [4] CANTO — CAN Time Out Detection
    0=NO_FAIL, Normal operation; 1=TIME_OUT, CAN Time Out detected
  [3] SYSERR — SWK System Error
    0=NO_FAIL, Selective Wake Mode is possible; 1=FAIL, System Error detected, SWK enabling not possible
  [2:1] CAN_FAIL — CAN failure status
    0=NO_ERR, No error; 1=CAN_TSD, CAN Thermal shutdown; 2=CAN_TXD_DOM_TO, CAN_TXD_DOM TXD dominant time out detected; 3=CAN_BUS_DOM_TO, CAN_BUS_DOM BUS dominant time out detected
  [0] VCAN_UV — Under Voltage CAN Bus Supply
    0=NORMAL, Normal operation; 1=UNDERVOLTAGE, CAN Supply undervoltage detected. Transmitter disabled
0x84 WK_STAT read-clear (reset mask 0x9B02) — Wake-up Source and Information Status
  [all] fields
    0=NO_WU, No Wake up; 1=WU, Wake up detected
  [9] CAN_WU — Wake up via CAN Bus
  [8] TIMER2_WU — Wake up via Timer2
  [7] TIMER1_WU — Wake up via Timer1
  [4] WK5_WU — Wake up via WK5
  [3] WK4_WU — Wake up via WK4
0x86 WK_LVL_STAT ro — WK Input Level
  [4] WK5_LVL — Status of WK5
    0=LOW, Low Level (=0); 1=HIGH, High Level (=1)
  [3] WK4_LVL — Status of WK4
    0=LOW, Low Level (=0); 1=HIGH, High Level (=1)
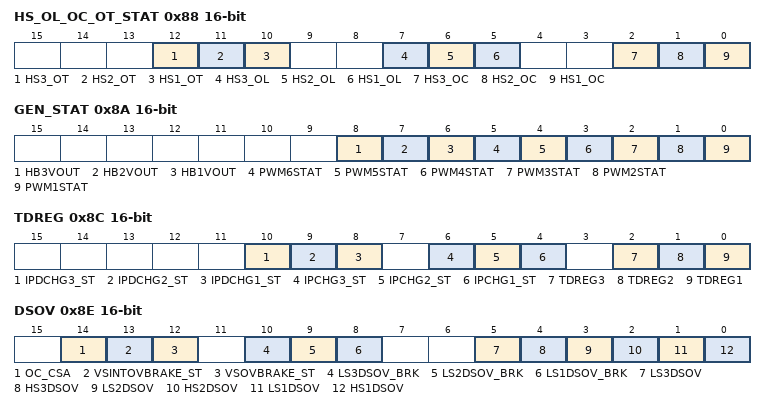
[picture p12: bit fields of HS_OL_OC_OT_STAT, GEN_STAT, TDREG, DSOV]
0x88 HS_OL_OC_OT_STAT read-clear (reset mask 0xFF) — High-Side Switch Status
  [12] HS3_OT — Overtemperature Detection on HS3
    0=NO_OT, No OT; 1=OT, OT detected
  [11] HS2_OT — Overtemperature Detection on HS2
    0=NO_OT, No OT; 1=OT, OT detected
  [10] HS1_OT — Overtemperature Detection on HS1
    0=NO_OT, No OT; 1=OT, OT detected
  [7] HS3_OL — Open-Load Detection on HS3
    0=NO_OL, No OL; 1=OL, OL detected
  [6] HS2_OL — Open-Load Detection on HS2
    0=NO_OL, No OL; 1=OL, OL detected
  [5] HS1_OL — Open-Load Detection on HS1
    0=NO_OL, No OL; 1=OL, OL detected
  [2] HS3_OC — Overcurrent Detection on HS3
    0=NO_OC, No OC; 1=OC, OC detected
  [1] HS2_OC — Overcurrent Detection on HS2
    0=NO_OC, No OC; 1=OC, OC detected
  [0] HS1_OC — Overcurrent Detection on HS1
    0=NO_OC, No OC; 1=OC, OC detected
0x8A GEN_STAT ro (reset mask 0xFF00) — General Status register
  [8] HB3VOUT — Voltage level at VSH3 when HB3MODE[10] = 11 and CPEN=1
    0=LOW, VSH3 = Low VS - VSH3 > VHS3VDSTHx; 1=HIGH, VSH3 = High VS - VSH3 VHS3VDSTHx
  [7] HB2VOUT — Voltage level at VSH2 when HB2MODE[10] = 11 and CPEN=1
    0=LOW, VSH2 = Low VS - VSH2 > VHS2VDSTHx; 1=HIGH, VSH2 = High VS - VSH2 VHS2VDSTHx
  [6] HB1VOUT — Voltage level at VSH1 when HB1MODE[10] = 11 and CPEN=1
    0=LOW, VSH1 = Low VS - VSH1 > VHS1VDSTHx; 1=HIGH, VSH1 = High VS - VSH1 VHS1VDSTHx
  [5] PWM6STAT — PWM6 status
    0=LOW, PWM6 is Low; 1=HIGH, PWM6 is High
  [4] PWM5STAT — PWM5 status
    0=LOW, PWM5 is Low; 1=HIGH, PWM5 is High
  [3] PWM4STAT — PWM4 Status
    0=LOW, PWM4 is Low; 1=HIGH, PWM4 is High
  [2] PWM3STAT — PWM3 status
    0=LOW, PWM3 is Low; 1=HIGH, PWM3 is High
  [1] PWM2STAT — PWM2 Status
    0=LOW, PWM2 is Low; 1=HIGH, PWM2 is High
  [0] PWM1STAT — PWM1/CRC status
    0=LOW, PWM1/CRC is Low; 1=HIGH, PWM1/CRC is High
0x8C TDREG ro (reset mask 0x7706) — Turn-on/off delay regulation register
  [10] IPDCHG3_ST — HB3 predischarge status
    0=CLAMP, the predischarge current is equal to; 2=0.5 mA typ. or ICHGMAX3 if AGC[10] = or 11B,; 1=NO_CLAMP, 0.5 mA < predischarge current < ICHGMAX31)
  [9] IPDCHG2_ST — HB2 predischarge status
    0=CLAMP, the predischarge current is equal to; 2=0.5 mA typ. or ICHGMAX2 if AGC[10] = or 11B,; 1=NO_CLAMP, 0.5 mA < predischarge current < ICHGMAX21)
  [8] IPDCHG1_ST — HB1 predischarge status
    0=CLAMP, the predischarge current is equal to the 0.5 mA typ. or ICHGMAX1 if AGC[10] = 1or 11B, and HBx_PWM_EN = 11); 1=NO_CLAMP, 0.5 mA < predischarge current < ICHGMAX11)
  [6] IPCHG3_ST — HB3 precharge status
    0=CLAMP, the precharge current is equal to 0.5 mA typ. or ICHGMAX3 if AGC[10] = 1or 11B, and HB3_PWM_EN = 11); 1=NO_CLAMP, 0.5 mA < precharge current < ICHGMAX31)
  [5] IPCHG2_ST — HB2 precharge status
    0=CLAMP, the precharge current is equal to 0.5 mA typ. or ICHGMAX2 if AGC[10] = 1or 11B, and HB2_PWM_EN = 11); 1=NO_CLAMP, 0.5 mA < precharge current < ICHGMAX21)
  [4] IPCHG1_ST — HB1 precharge status
    0=CLAMP, the precharge current is equal to the 0.5 mA typ. or ICHGMAX1 if AGC[10] = 1or 11B, and HB1_PWM_EN = 11); 1=NO_CLAMP, 0.5 mA < precharge current < ICHGMAX11)
  [2] TDREG3 — HB3 Regulation of turn-on/off delay
    0=NO_REG, tDON3 and tDOFF3 are not in regulation; 1=REG, tDON3 and/or tDOFF3 are in regulation
  [1] TDREG2 — HB2 Regulation of turn-on/off delay
    0=NO_REG, tDON2 and tDOFF2 are not in regulation; 1=REG, tDON2 and/or tDOFF2 are in regulation
  [0] TDREG1 — HB1 Regulation of turn-on/off delay
    0=NO_REG, tDON and tDOFF are not in regulation; 1=REG, tDON and/or tDOFF are in regulation
0x8E DSOV read-clear (reset mask 0x7F76) — Drain-source overvoltage
  [14] OC_CSA — CSA Overcurrent detection
    0=NO_OC, No overcurrent detected; 1=OC, Overcurrent detected
  [13] VSINTOVBRAKE_ST — VSINT Brake status
    0=NOT_DETECT, VSINT overvoltage brake condition is not detected; 1=DETECT, VSINT overvoltage brake conditions is detected
  [12] VSOVBRAKE_ST — VS Brake status
    0=NOT_DETECT, VS overvoltage brake conditions is not detected; 1=DETECT, VS overvoltage brake conditions is detected
  [10] LS3DSOV_BRK — Drain-source overvoltage on low-side 3 during braking
    0=NO_OV, No drain-source overvoltage on LS3; 1=OV, Drain-source overvoltage on LS3
  [9] LS2DSOV_BRK — Drain-source overvoltage on low-side 2 during braking
    0=NO_OV, No drain-source overvoltage on LS2; 1=OV, Drain-source overvoltage on LS2
  [8] LS1DSOV_BRK — Drain-source overvoltage on low-side 1 during braking
    0=NO_OV, No drain-source overvoltage on LS1; 1=OV, Drain-source overvoltage on LS1
  [5] LS3DSOV — Drain-source overvoltage on low-side 3
    values as LS3DSOV_BRK
  [4] HS3DSOV — Drain-source overvoltage on high-side 3
    0=NO_OV, No drain-source overvoltage on HS3; 1=OV, Drain-source overvoltage on HS3
  [3] LS2DSOV — Drain-source overvoltage on low-side 2
    values as LS2DSOV_BRK
  [2] HS2DSOV — Drain-source overvoltage on high-side 2
    0=NO_OV, No drain-source overvoltage on HS2; 1=OV, Drain-source overvoltage on HS2
  [1] LS1DSOV — Drain-source overvoltage on low-side 1
    values as LS1DSOV_BRK
  [0] HS1DSOV — Drain-source overvoltage on high-side 1
    0=NO_OV, No drain-source overvoltage on HS1; 1=OV, Drain-source overvoltage on HS1
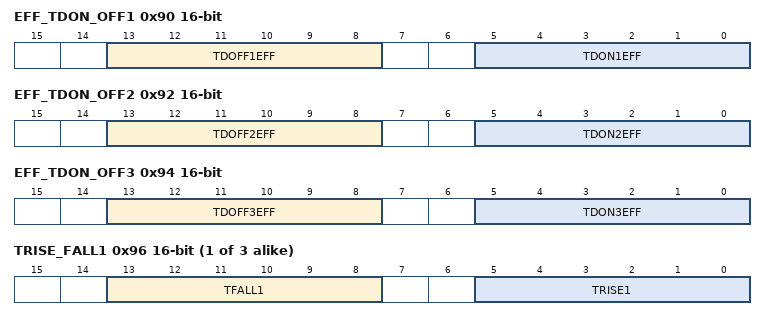
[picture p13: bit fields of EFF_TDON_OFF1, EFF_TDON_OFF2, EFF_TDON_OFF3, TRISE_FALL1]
0x90 EFF_TDON_OFF1 ro (reset mask 0x3F3E) — Effective MOSFET turn.on/off delay - HB1
  [13:8] TDOFF1EFF — Effective active MOSFET turn-off delay HB1
  [5:0] TDON1EFF — Effective active MOSFET turn-on delay HB1 Nominal effective tDON1 = 53.3 ns x TDON1EFF[50]D
0x92 EFF_TDON_OFF2 ro (reset mask 0x3F3E) — Effective MOSFET turn.on/off delay - HB 2
  [13:8] TDOFF2EFF — Effective active MOSFET turn-off delay HB2
  [5:0] TDON2EFF — Effective active MOSFET turn-on delay HB2 Nominal effective tDON2 = 53.3 ns x TDON2EFF[50]D
0x94 EFF_TDON_OFF3 ro (reset mask 0x3F3E) — Effective MOSFET turn.on/off delay - HB3
  [13:8] TDOFF3EFF — Effective active MOSFET turn-off delay HB3 Nominal effective tDOFF3 = 53.3 ns x TDO3EFF[138]D
  [5:0] TDON3EFF — Effective active MOSFET turn-on delay HB3 Nominal effective tDON3 = 53.3 ns x TDON3EFF[50]D
{0x94+2i} TRISE_FALL{i} ro (reset mask 0x3F3E) (i=1..3) — MOSFET rise/fall time - HB{i}
  [13:8] TFALL{i} — Active MOSFET fall time HB{i}
  [5:0] TRISE{i} — Active MOSFET rise time HB{i}
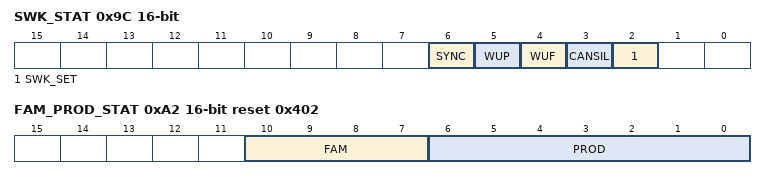
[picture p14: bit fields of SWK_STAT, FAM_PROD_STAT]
0x9C SWK_STAT access per field — Selective Wake Status
  [6] SYNC ro — Synchronisation (at least one CAN frame without fail must have been received)
    0=NO_SYNC, SWK function not working or not synchronous to CAN bus; 1=SYNC, Valid CAN frame received, SWK function is synchronous to CAN bus
  [5] WUP read-clear — Wake-up Pattern Detection
    0=NO_WUP, No WUP; 1=WUP_DETECTED, WUP detected
  [4] WUF read-clear — SWK Wake-up Frame Detection
    0=NO_WUF, No WUF; 1=WUF_DETECTED, WUF detected
  [3] CANSIL ro — CAN Silent Time during SWK operation
    0=NO_SIL, tsilence not exceeded; 1=SIL_EXCEEDED, set if tsilence is exceeded
  [2] SWK_SET ro — Selective Wake Activity
    0=INACTIVE, Selective Wake is not active; 1=ACTIVE, Selective Wake is activated
0x9E SWK_ECNT_STAT ro — Selective Wake ECNT Status
  [5:0] ECNT — SWK CAN Frame Error Counter
0xA0 SWK_CDR_STAT ro reset 0xA000 — Selective Wake CDR Status
  [15:4] N_AVG — Output Value from Filter Block
0xA2 FAM_PROD_STAT ro reset 0x402 (reset mask 0xFF06) — Family and Product Identification Register
  [10:7] FAM — Device Family Identifier
  [6:0] PROD — Device Product Identifier
